AUTOSAR XML (schema 4.0)
package /Interfaces
  sender receiver interface SpeedIf
    data value
  client server interface LogIf
    operation Write
package /Swcs
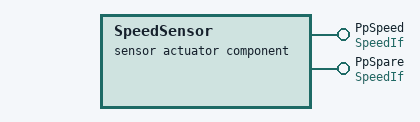
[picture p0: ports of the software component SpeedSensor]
  sensor actuator sw component type SpeedSensor
    provide port PpSpeed: provided-interface=SpeedIf
    provide port PpSpare: provided-interface=SpeedIf
  application sw component type BrakeCtrl
    require port RpSpeed: required-interface=SpeedIf
  service sw component type DiagLogger
    provide port PpLog: provided-interface=LogIf
  composition sw component type Vehicle
    component speed: type=SpeedSensor
    component brake: type=BrakeCtrl
    connect speed.PpSpeed -> brake.RpSpeed
